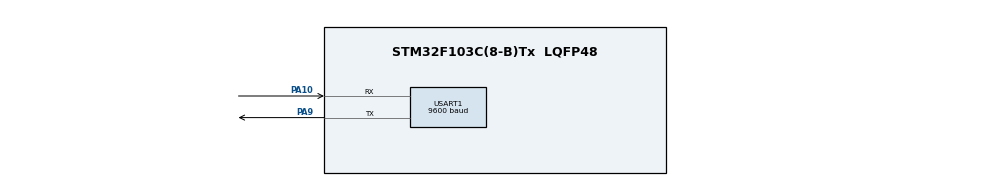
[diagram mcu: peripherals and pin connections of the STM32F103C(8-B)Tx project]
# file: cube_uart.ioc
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Mcu.Family=STM32F1
Mcu.Name=STM32F103C(8-B)Tx
Mcu.Package=LQFP48
NVIC.PriorityGroup=NVIC_PRIORITYGROUP_4
PA10.Mode=Asynchronous
PA10.Signal=USART1_RX
PA9.Mode=Asynchronous
PA9.Signal=USART1_TX
PD0-OSC_IN.Mode=HSE-External-Oscillator
PD0-OSC_IN.Signal=RCC_OSC_IN
PD1-OSC_OUT.Mode=HSE-External-Oscillator
PD1-OSC_OUT.Signal=RCC_OSC_OUT
ProjectManager.TargetToolchain=SW4STM32
RCC.APB1Freq_Value=8000000
RCC.APB2Freq_Value=8000000
USART1.BaudRate=9600
board=cube_uart

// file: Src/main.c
/**
  ******************************************************************************
  * File Name          : main.c
  * Description        : Main program body
  ******************************************************************************
  *
  * COPYRIGHT(c) 2018 STMicroelectronics
  *
  * Redistribution and use in source and binary forms, with or without modification,
  * are permitted provided that the following conditions are met:
  *   1. Redistributions of source code must retain the above copyright notice,
  *      this list of conditions and the following disclaimer.
  *   2. Redistributions in binary form must reproduce the above copyright notice,
  *      this list of conditions and the following disclaimer in the documentation
  *      and/or other materials provided with the distribution.
  *   3. Neither the name of STMicroelectronics nor the names of its contributors
  *      may be used to endorse or promote products derived from this software
  *      without specific prior written permission.
  *
  * THIS SOFTWARE IS PROVIDED BY THE COPYRIGHT HOLDERS AND CONTRIBUTORS "AS IS"
  * AND ANY EXPRESS OR IMPLIED WARRANTIES, INCLUDING, BUT NOT LIMITED TO, THE
  * IMPLIED WARRANTIES OF MERCHANTABILITY AND FITNESS FOR A PARTICULAR PURPOSE ARE
  * DISCLAIMED. IN NO EVENT SHALL THE COPYRIGHT HOLDER OR CONTRIBUTORS BE LIABLE
  * FOR ANY DIRECT, INDIRECT, INCIDENTAL, SPECIAL, EXEMPLARY, OR CONSEQUENTIAL
  * DAMAGES (INCLUDING, BUT NOT LIMITED TO, PROCUREMENT OF SUBSTITUTE GOODS OR
  * SERVICES; LOSS OF USE, DATA, OR PROFITS; OR BUSINESS INTERRUPTION) HOWEVER
  * CAUSED AND ON ANY THEORY OF LIABILITY, WHETHER IN CONTRACT, STRICT LIABILITY,
  * OR TORT (INCLUDING NEGLIGENCE OR OTHERWISE) ARISING IN ANY WAY OUT OF THE USE
  * OF THIS SOFTWARE, EVEN IF ADVISED OF THE POSSIBILITY OF SUCH DAMAGE.
  *
  ******************************************************************************
  */
#include "stm32f1xx_hal.h"
#include "usart.h"
#include "gpio.h"

/* USER CODE BEGIN PV */
/* Private variables ---------------------------------------------------------*/
uint8_t pdata;
/* USER CODE END PV */

void SystemClock_Config(void);

/* USER CODE BEGIN PFP */
/* Private function prototypes -----------------------------------------------*/

/* USER CODE END PFP */

int main(void)
{

  /* MCU Configuration----------------------------------------------------------*/

  /* Reset of all peripherals, Initializes the Flash interface and the Systick. */
  HAL_Init();

  /* Configure the system clock */
  SystemClock_Config();

  /* Initialize all configured peripherals */
  MX_GPIO_Init();
  MX_USART1_UART_Init();

  /* Infinite loop */
  while (1)
  {

  /* USER CODE BEGIN 3 */
    HAL_UART_Receive(&huart1, &pdata, 1, 0xFFFF);
    while(pdata!='\n'){
      HAL_UART_Transmit(&huart1,&pdata,1,0xFFFF);
      HAL_UART_Receive(&huart1,&pdata,1,0xFFFF);
    }
    pdata = '\n';
    HAL_UART_Transmit(&huart1,&pdata,1,0xFFFF);
  }
  /* USER CODE END 3 */

}

/** System Clock Configuration
*/
void SystemClock_Config(void)
{

  RCC_OscInitTypeDef RCC_OscInitStruct;
  RCC_ClkInitTypeDef RCC_ClkInitStruct;

  RCC_OscInitStruct.OscillatorType = RCC_OSCILLATORTYPE_HSI;
  RCC_OscInitStruct.HSIState = RCC_HSI_ON;
  RCC_OscInitStruct.HSICalibrationValue = 16;
  RCC_OscInitStruct.PLL.PLLState = RCC_PLL_NONE;
  HAL_RCC_OscConfig(&RCC_OscInitStruct);

  RCC_ClkInitStruct.ClockType = RCC_CLOCKTYPE_SYSCLK;
  RCC_ClkInitStruct.SYSCLKSource = RCC_SYSCLKSOURCE_HSI;
  RCC_ClkInitStruct.AHBCLKDivider = RCC_SYSCLK_DIV1;
  RCC_ClkInitStruct.APB1CLKDivider = RCC_HCLK_DIV1;
  RCC_ClkInitStruct.APB2CLKDivider = RCC_HCLK_DIV1;
  HAL_RCC_ClockConfig(&RCC_ClkInitStruct, FLASH_LATENCY_0);

  HAL_SYSTICK_Config(HAL_RCC_GetHCLKFreq()/1000);

  HAL_SYSTICK_CLKSourceConfig(SYSTICK_CLKSOURCE_HCLK);

}

/************************ (C) COPYRIGHT STMicroelectronics *****END OF FILE****/
